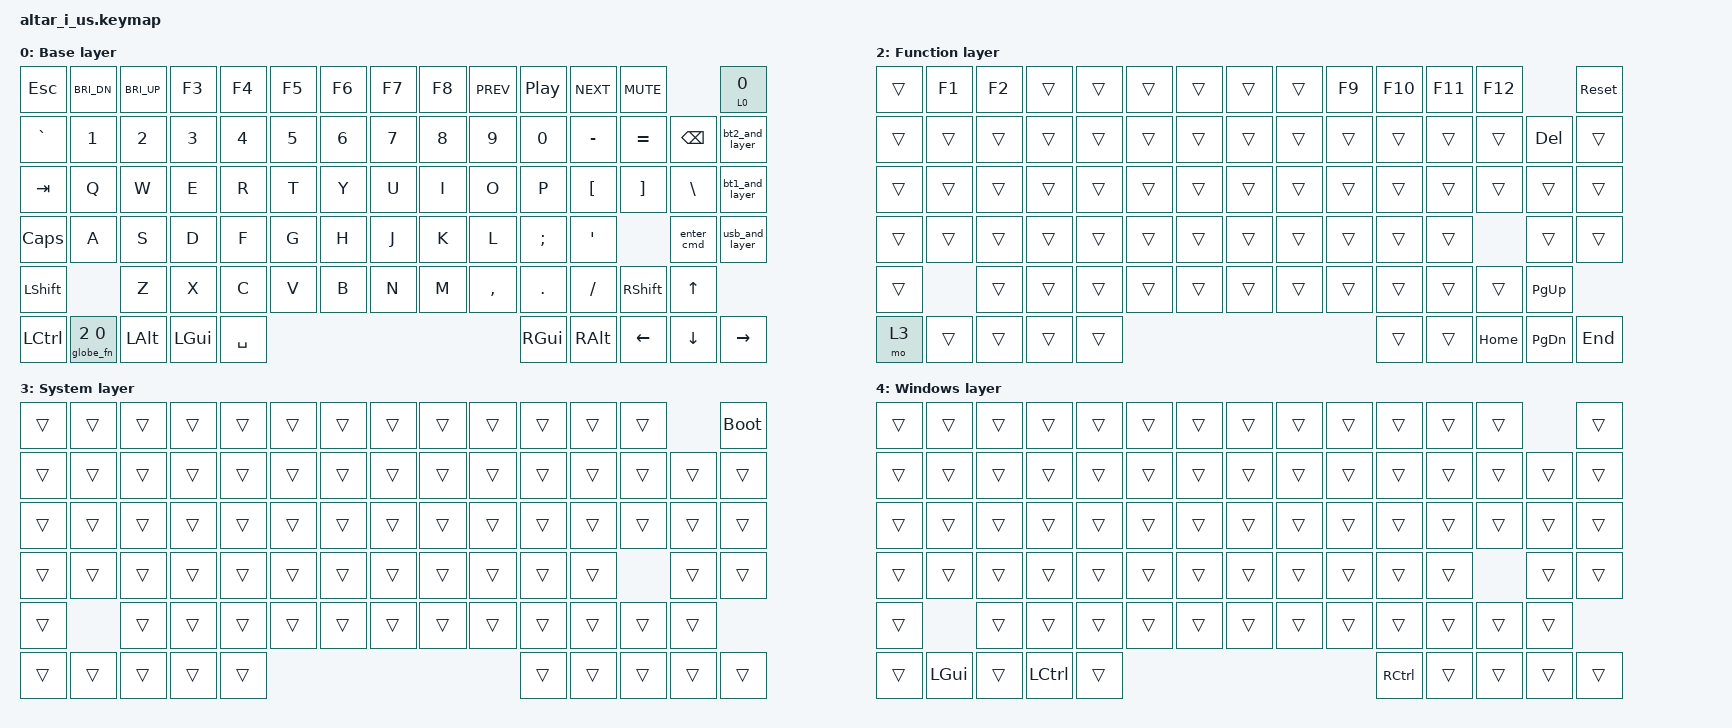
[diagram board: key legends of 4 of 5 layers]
/*
 * Copyright (c) 2025 Electronic Materials Office Limited
 *
 * SPDX-License-Identifier: MIT
 */

#include <behaviors.dtsi>
#include <dt-bindings/zmk/keys.h>
#include <dt-bindings/zmk/bt.h>
#include <dt-bindings/zmk/outputs.h>
#include "altar_i_keymap_common.dtsi"

/ {
	keymap {
		compatible = "zmk,keymap";

		default_layer {
			display-name = "Base layer";
			// ---------------------------------------------------------------------------------------------------------
			// | ESC   | BRI_DN| BRI_UP| F3    | F4    | F5    | F6    | F7    | F8    | PREV  | P/P   | NEXT  | MUTE  |                       PAIR |
			// | ~     | 1     | 2     | 3     | 4     | 5     | 6     | 7     | 8     | 9     | 0     | -     |  =    | BSPC  |               BT2  |
			// | TAB   | Q     | W     | E     | R     | T     | Y     | U     | I     | O     | P     | [     |  ]    | BSLH  |               BT1  |
			// | CAPS  | A     | S     | D     | F     | G     | H     | J     | K     | L     | ;     | '     |         ENTER |               USB  |
			// | SHIFT         | Z     | X     | C     | V     | B     | N     | M     | ,     | .     | /     | SHFT  | UP    |
			// | CTRL   | FN1  | ALT   | WIN   |                 SPACE                         | WIN   | ALT   | LFT   | DWN   | RGT   |

			bindings = <
			&kp ESC          &kp C_BRI_DN     &kp C_BRI_UP     &kp F3        &kp F4        &kp F5           &kp F6           &kp F7           &kp F8           &kp C_PREV       &kp C_PLAY_PAUSE &kp C_NEXT       &kp C_MUTE                                      &ht_bt_clr 0 0
			&kp GRAVE        &kp N1           &kp N2           &kp N3        &kp N4        &kp N5           &kp N6           &kp N7           &kp N8           &kp N9           &kp N0           &kp MINUS        &kp EQUAL        &kp BSPC                       &bt2_and_layer
			&kp TAB          &kp Q            &kp W            &kp E         &kp R         &kp T            &kp Y            &kp U            &kp I            &kp O            &kp P            &kp LBKT         &kp RBKT         &kp BSLH                       &bt1_and_layer
			&kp CAPS         &kp A            &kp S            &kp D         &kp F         &kp G            &kp H            &kp J            &kp K            &kp L            &kp SEMI         &kp SQT                           &enter_cmd                     &usb_and_layer
			&kp LSHIFT                        &kp Z            &kp X         &kp C         &kp V            &kp B            &kp N            &kp M            &kp COMMA        &kp  DOT         &kp FSLH         &kp RSHIFT       &kp UP
			&kp LCTRL        &globe_fn 2 0    &kp LALT         &kp LGUI                                     &kp SPACE                                                           &kp  RGUI        &kp RALT         &kp LEFT         &kp DOWN         &kp RIGHT
			>;

			sensor-bindings = <&inc_dec_kp C_VOL_UP C_VOL_DN>;
		};

		usb_layer {
			display-name = "USB layer";
			// ---------------------------------------------------------------------------------------------------------
			// |       |       |       |       |       |       |       |       |       |       |       |       |       |                      NONE  |
			// |       |       |       |       |       |       |       |       |       |       |       |       |       |       |                    |
			// |       |       |       |       |       |       |       |       |       |       |       |       |       |       |                    |
			// |       |       |       |       |       |       |       |       |       |       |       |       |       |       |                    |
			// |       |       |       |       |       |       |       |       |       |       |       |       |       |       |
			// |       |       |       |       |                                               |       |       |       |       |       |

			bindings = <
			&trans           &trans           &trans           &trans        &trans        &trans           &trans           &trans           &trans           &trans           &trans           &trans           &trans                                          &none
			&trans           &trans           &trans           &trans        &trans        &trans           &trans           &trans           &trans           &trans           &trans           &trans           &trans           &trans                         &trans
			&trans           &trans           &trans           &trans        &trans        &trans           &trans           &trans           &trans           &trans           &trans           &trans           &trans           &trans                         &trans
			&trans           &trans           &trans           &trans        &trans        &trans           &trans           &trans           &trans           &trans           &trans           &trans           &trans                                          &trans
			&trans           &trans           &trans           &trans        &trans        &trans           &trans           &trans           &trans           &trans           &trans           &trans           &trans           &trans
			&trans           &trans           &trans           &trans                                       &trans                                                              &trans           &trans           &trans           &trans           &trans
			>;

			sensor-bindings = <&inc_dec_kp C_VOL_UP C_VOL_DN>;
		};

		fn_layer {
			display-name = "Function layer";
			// ---------------------------------------------------------------------------------------------------------
			// |       | F1    | F2    |       |       |       |       |       |       | F9    | F10   | F11   |  F12  |                            |
			// |       |       |       |       |       |       |       |       |       |       |       |       |       |       |                    |
			// |       |       |       |       |       |       |       |       |       |       |       |       |       |       |                    |
			// |       |       |       |       |       |       |       |       |       |       |       |       |       |       |              RESET |
			// |       |       |       |       |       |       |       |       |       |       |       |       |       |       |
			// |       | FN2   |       |       |                                               |       |       |       |       |       |

			bindings = <
			&trans           &kp F1           &kp F2           &trans        &trans        &trans           &trans           &trans           &trans           &kp F9           &kp F10          &kp F11          &kp F12                                         &sys_reset
			&trans           &trans           &trans           &trans        &trans        &trans           &trans           &trans           &trans           &trans           &trans           &trans           &trans           &kp DEL                        &trans
			&trans           &trans           &trans           &trans        &trans        &trans           &trans           &trans           &trans           &trans           &trans           &trans           &trans           &trans                         &trans
			&trans           &trans           &trans           &trans        &trans        &trans           &trans           &trans           &trans           &trans           &trans           &trans           &trans                                          &trans
			&trans                            &trans           &trans        &trans        &trans           &trans           &trans           &trans           &trans           &trans           &trans           &trans           &kp PAGE_UP
			&mo 3            &trans            &trans           &trans                                       &trans                                                              &trans           &trans           &kp HOME         &kp PAGE_DOWN      &kp END
			>;

			sensor-bindings = <&inc_dec_kp LG(LS(EQUAL)) LG(MINUS)>;
		};

		sys_layer {
			display-name = "System layer";
			// ---------------------------------------------------------------------------------------------------------
			// |       |       |       |       |       |       |       |       |       |       |       |       |       |                            |
			// |       |       |       |       |       |       |       |       |       |       |       |       |       |       |                    |
			// |       |       |       |       |       |       |       |       |       |       |       |       |       |       |                    |
			// |       |       |       |       |       |       |       |       |       |       |       |       |       |       |         BOOTLOADER |
			// |       |       |       |       |       |       |       |       |       |       |       |       |       |       |
			// |       |       |       |       |                                               |       |       |       |       |       |

			bindings = <
			&trans           &trans           &trans           &trans        &trans        &trans           &trans           &trans           &trans           &trans           &trans           &trans           &trans                                          &bootloader
			&trans           &trans           &trans           &trans        &trans        &trans           &trans           &trans           &trans           &trans           &trans           &trans           &trans           &trans                         &trans
			&trans           &trans           &trans           &trans        &trans        &trans           &trans           &trans           &trans           &trans           &trans           &trans           &trans           &trans                         &trans
			&trans           &trans           &trans           &trans        &trans        &trans           &trans           &trans           &trans           &trans           &trans           &trans           &trans                                          &trans
			&trans                            &trans           &trans        &trans        &trans           &trans           &trans           &trans           &trans           &trans           &trans           &trans           &trans
			&trans           &trans           &trans           &trans                                       &trans                                                              &trans           &trans           &trans           &trans           &trans
			>;

			sensor-bindings = <&inc_dec_kp C_PREV C_NEXT>;
		};

		windows_layer {
			display-name = "Windows layer";
			// ---------------------------------------------------------------------------------------------------------
			// |       |       |       |       |       |       |       |       |       |       |       |       |       |                            |
			// |       |       |       |       |       |       |       |       |       |       |       |       |       |       |                    |
			// |       |       |       |       |       |       |       |       |       |       |       |       |       |       |                    |
			// |       |       |       |       |       |       |       |       |       |       |       |       |       |       |                    |
			// |       |       |       |       |       |       |       |       |       |       |       |       |       |       |
			// |       |       |       |       |                                               |       |       |       |       |       |

			bindings = <
			&trans           &trans           &trans           &trans        &trans        &trans           &trans           &trans           &trans           &trans           &trans           &trans           &trans                                          &trans
			&trans           &trans           &trans           &trans        &trans        &trans           &trans           &trans           &trans           &trans           &trans           &trans           &trans           &trans                         &trans
			&trans           &trans           &trans           &trans        &trans        &trans           &trans           &trans           &trans           &trans           &trans           &trans           &trans           &trans                         &trans
			&trans           &trans           &trans           &trans        &trans        &trans           &trans           &trans           &trans           &trans           &trans           &trans                            &trans                         &trans
			&trans                            &trans           &trans        &trans        &trans           &trans           &trans           &trans           &trans           &trans           &trans           &trans           &trans
			&trans           &kp LGUI         &trans           &kp LCTRL                                    &trans                                                              &kp RCTRL        &trans           &trans           &trans           &trans
			>;

			sensor-bindings = <&inc_dec_kp C_VOL_UP C_VOL_DN>;
		};

	};
};
